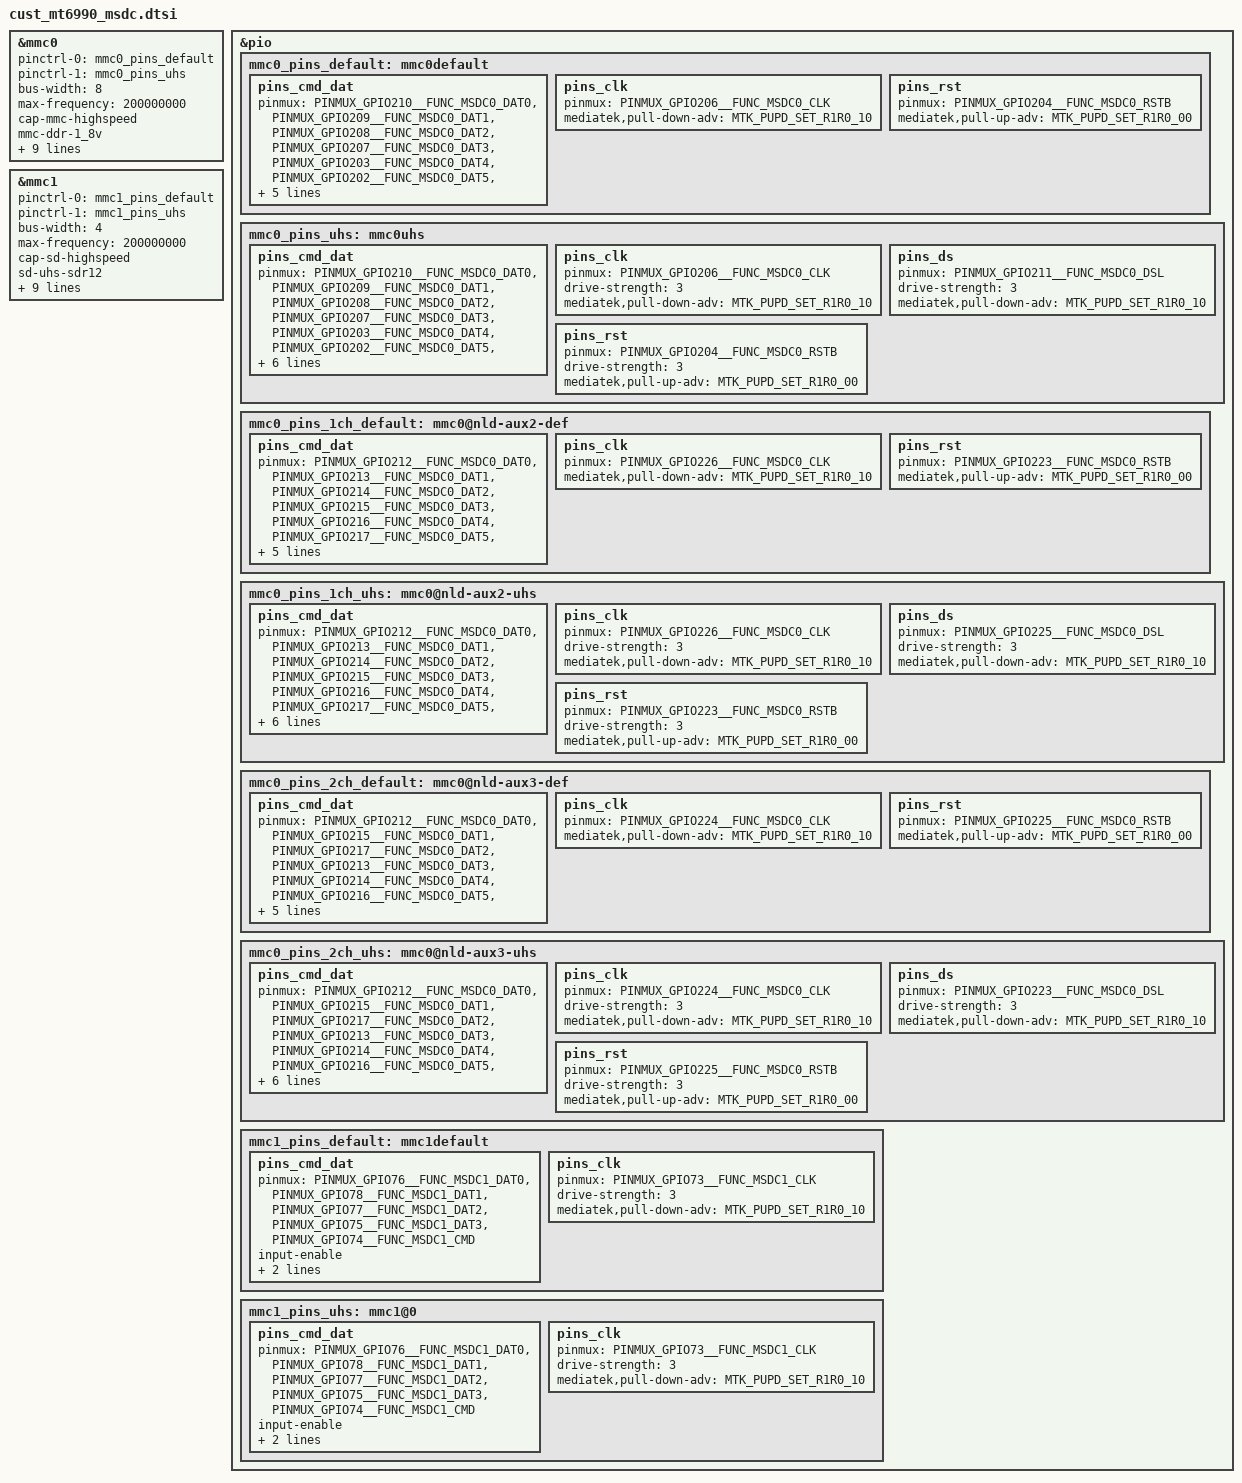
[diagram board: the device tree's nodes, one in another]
// SPDX-License-Identifier: GPL-2.0
/*
 * Copyright (c) 2019 MediaTek Inc.
 */
/********************************************
 * MT6890 MSDC DTSI File
 ********************************************/
#include <dt-bindings/gpio/gpio.h>

&mmc0 {
	pinctrl-names = "default", "state_uhs";
	pinctrl-0 = <&mmc0_pins_default>;
	pinctrl-1 = <&mmc0_pins_uhs>;
	bus-width = <8>;
	max-frequency = <200000000>;
	cap-mmc-highspeed;
	mmc-ddr-1_8v;
	mmc-hs200-1_8v;
	mmc-hs400-1_8v;
	cap-mmc-hw-reset;
	no-sdio;
	no-sd;
	hs400-ds-delay = <0x12814>;
	supports-cqe;
	power-gpio = <&pio 102 GPIO_ACTIVE_LOW>;
	non-removable;
};

&pio {
	mmc0_pins_default: mmc0default {
		pins_cmd_dat {
			pinmux = <PINMUX_GPIO210__FUNC_MSDC0_DAT0>,
					 <PINMUX_GPIO209__FUNC_MSDC0_DAT1>,
					 <PINMUX_GPIO208__FUNC_MSDC0_DAT2>,
					 <PINMUX_GPIO207__FUNC_MSDC0_DAT3>,
					 <PINMUX_GPIO203__FUNC_MSDC0_DAT4>,
					 <PINMUX_GPIO202__FUNC_MSDC0_DAT5>,
					 <PINMUX_GPIO201__FUNC_MSDC0_DAT6>,
					 <PINMUX_GPIO200__FUNC_MSDC0_DAT7>,
					 <PINMUX_GPIO205__FUNC_MSDC0_CMD>;
			input-enable;
			mediatek,pull-up-adv = <MTK_PUPD_SET_R1R0_01>;
		};
		pins_clk {
			pinmux = <PINMUX_GPIO206__FUNC_MSDC0_CLK>;
			mediatek,pull-down-adv = <MTK_PUPD_SET_R1R0_10>;
		};

		pins_rst {
			pinmux = <PINMUX_GPIO204__FUNC_MSDC0_RSTB>;
			mediatek,pull-up-adv = <MTK_PUPD_SET_R1R0_00>;
		};
	};
	mmc0_pins_uhs: mmc0uhs{
		pins_cmd_dat {
			pinmux = <PINMUX_GPIO210__FUNC_MSDC0_DAT0>,
					 <PINMUX_GPIO209__FUNC_MSDC0_DAT1>,
					 <PINMUX_GPIO208__FUNC_MSDC0_DAT2>,
					 <PINMUX_GPIO207__FUNC_MSDC0_DAT3>,
					 <PINMUX_GPIO203__FUNC_MSDC0_DAT4>,
					 <PINMUX_GPIO202__FUNC_MSDC0_DAT5>,
					 <PINMUX_GPIO201__FUNC_MSDC0_DAT6>,
					 <PINMUX_GPIO200__FUNC_MSDC0_DAT7>,
					 <PINMUX_GPIO205__FUNC_MSDC0_CMD>;
			input-enable;
			drive-strength = <3>;
			mediatek,pull-up-adv = <MTK_PUPD_SET_R1R0_01>;
		};
		pins_clk {
			pinmux = <PINMUX_GPIO206__FUNC_MSDC0_CLK>;
			drive-strength = <3>;
			mediatek,pull-down-adv = <MTK_PUPD_SET_R1R0_10>;
		};
		pins_ds {
			pinmux = <PINMUX_GPIO211__FUNC_MSDC0_DSL>;
			drive-strength = <3>;
			mediatek,pull-down-adv = <MTK_PUPD_SET_R1R0_10>;
		};
		pins_rst {
			pinmux = <PINMUX_GPIO204__FUNC_MSDC0_RSTB>;
			drive-strength = <3>;
			mediatek,pull-up-adv = <MTK_PUPD_SET_R1R0_00>;
		};
	};
	mmc0_pins_1ch_default: mmc0@nld-aux2-def{
		pins_cmd_dat {
			pinmux = <PINMUX_GPIO212__FUNC_MSDC0_DAT0>,
					 <PINMUX_GPIO213__FUNC_MSDC0_DAT1>,
					 <PINMUX_GPIO214__FUNC_MSDC0_DAT2>,
					 <PINMUX_GPIO215__FUNC_MSDC0_DAT3>,
					 <PINMUX_GPIO216__FUNC_MSDC0_DAT4>,
					 <PINMUX_GPIO217__FUNC_MSDC0_DAT5>,
					 <PINMUX_GPIO218__FUNC_MSDC0_DAT6>,
					 <PINMUX_GPIO219__FUNC_MSDC0_DAT7>,
					 <PINMUX_GPIO224__FUNC_MSDC0_CMD>;
			input-enable;
			mediatek,pull-up-adv = <MTK_PUPD_SET_R1R0_01>;
		};
		pins_clk {
			pinmux = <PINMUX_GPIO226__FUNC_MSDC0_CLK>;
			mediatek,pull-down-adv = <MTK_PUPD_SET_R1R0_10>;
		};

		pins_rst {
			pinmux = <PINMUX_GPIO223__FUNC_MSDC0_RSTB>;
			mediatek,pull-up-adv = <MTK_PUPD_SET_R1R0_00>;
		};
	};

	mmc0_pins_1ch_uhs: mmc0@nld-aux2-uhs{
		pins_cmd_dat {
			pinmux = <PINMUX_GPIO212__FUNC_MSDC0_DAT0>,
					 <PINMUX_GPIO213__FUNC_MSDC0_DAT1>,
					 <PINMUX_GPIO214__FUNC_MSDC0_DAT2>,
					 <PINMUX_GPIO215__FUNC_MSDC0_DAT3>,
					 <PINMUX_GPIO216__FUNC_MSDC0_DAT4>,
					 <PINMUX_GPIO217__FUNC_MSDC0_DAT5>,
					 <PINMUX_GPIO218__FUNC_MSDC0_DAT6>,
					 <PINMUX_GPIO219__FUNC_MSDC0_DAT7>,
					 <PINMUX_GPIO224__FUNC_MSDC0_CMD>;
			input-enable;
			drive-strength = <3>;
			mediatek,pull-up-adv = <MTK_PUPD_SET_R1R0_01>;
		};
		pins_clk {
			pinmux = <PINMUX_GPIO226__FUNC_MSDC0_CLK>;
			drive-strength = <3>;
			mediatek,pull-down-adv = <MTK_PUPD_SET_R1R0_10>;
		};
		pins_ds {
			pinmux = <PINMUX_GPIO225__FUNC_MSDC0_DSL>;
			drive-strength = <3>;
			mediatek,pull-down-adv = <MTK_PUPD_SET_R1R0_10>;
		};
		pins_rst {
			pinmux = <PINMUX_GPIO223__FUNC_MSDC0_RSTB>;
			drive-strength = <3>;
			mediatek,pull-up-adv = <MTK_PUPD_SET_R1R0_00>;
		};
	};

	mmc0_pins_2ch_default: mmc0@nld-aux3-def{
		pins_cmd_dat {
			pinmux = <PINMUX_GPIO212__FUNC_MSDC0_DAT0>,
					 <PINMUX_GPIO215__FUNC_MSDC0_DAT1>,
					 <PINMUX_GPIO217__FUNC_MSDC0_DAT2>,
					 <PINMUX_GPIO213__FUNC_MSDC0_DAT3>,
					 <PINMUX_GPIO214__FUNC_MSDC0_DAT4>,
					 <PINMUX_GPIO216__FUNC_MSDC0_DAT5>,
					 <PINMUX_GPIO218__FUNC_MSDC0_DAT6>,
					 <PINMUX_GPIO219__FUNC_MSDC0_DAT7>,
					 <PINMUX_GPIO226__FUNC_MSDC0_CMD>;
			input-enable;
			mediatek,pull-up-adv = <MTK_PUPD_SET_R1R0_01>;
		};
		pins_clk {
			pinmux = <PINMUX_GPIO224__FUNC_MSDC0_CLK>;
			mediatek,pull-down-adv = <MTK_PUPD_SET_R1R0_10>;
		};

		pins_rst {
			pinmux = <PINMUX_GPIO225__FUNC_MSDC0_RSTB>;
			mediatek,pull-up-adv = <MTK_PUPD_SET_R1R0_00>;
		};
	};
	mmc0_pins_2ch_uhs: mmc0@nld-aux3-uhs{
		pins_cmd_dat {
			pinmux = <PINMUX_GPIO212__FUNC_MSDC0_DAT0>,
					 <PINMUX_GPIO215__FUNC_MSDC0_DAT1>,
					 <PINMUX_GPIO217__FUNC_MSDC0_DAT2>,
					 <PINMUX_GPIO213__FUNC_MSDC0_DAT3>,
					 <PINMUX_GPIO214__FUNC_MSDC0_DAT4>,
					 <PINMUX_GPIO216__FUNC_MSDC0_DAT5>,
					 <PINMUX_GPIO218__FUNC_MSDC0_DAT6>,
					 <PINMUX_GPIO219__FUNC_MSDC0_DAT7>,
					 <PINMUX_GPIO226__FUNC_MSDC0_CMD>;
			input-enable;
			drive-strength = <3>;
			mediatek,pull-up-adv = <MTK_PUPD_SET_R1R0_01>;
		};
		pins_clk {
			pinmux = <PINMUX_GPIO224__FUNC_MSDC0_CLK>;
			drive-strength = <3>;
			mediatek,pull-down-adv = <MTK_PUPD_SET_R1R0_10>;
		};
		pins_ds {
			pinmux = <PINMUX_GPIO223__FUNC_MSDC0_DSL>;
			drive-strength = <3>;
			mediatek,pull-down-adv = <MTK_PUPD_SET_R1R0_10>;
		};
		pins_rst {
			pinmux = <PINMUX_GPIO225__FUNC_MSDC0_RSTB>;
			drive-strength = <3>;
			mediatek,pull-up-adv = <MTK_PUPD_SET_R1R0_00>;
		};
	};
};

&mmc1 {
	pinctrl-names = "default", "state_uhs";
	pinctrl-0 = <&mmc1_pins_default>;
	pinctrl-1 = <&mmc1_pins_uhs>;
//	pinctrl-2 = <&mmc1_a_pins_default>;
//	pinctrl-3 = <&mmc1_a_pins_uhs>;
	bus-width = <4>;
	max-frequency = <200000000>;
	cap-sd-highspeed;
	sd-uhs-sdr12;
	sd-uhs-sdr25;
	sd-uhs-sdr50;
	sd-uhs-sdr104;
	sd-uhs-ddr50;
	cd-gpios = <&pio 99 GPIO_ACTIVE_LOW>;
	power-gpio = <&pio 153 GPIO_ACTIVE_HIGH>;
	vqmmc-supply = <&mt6361_ldo28_vmc_reg>;
	no-mmc;
	no-sdio;
};

&pio {
#if 1
	mmc1_pins_default: mmc1default {
		pins_cmd_dat {
			pinmux = <PINMUX_GPIO76__FUNC_MSDC1_DAT0>,
					 <PINMUX_GPIO78__FUNC_MSDC1_DAT1>,
					 <PINMUX_GPIO77__FUNC_MSDC1_DAT2>,
					 <PINMUX_GPIO75__FUNC_MSDC1_DAT3>,
					 <PINMUX_GPIO74__FUNC_MSDC1_CMD>;
			input-enable;
			drive-strength = <3>;
			mediatek,pull-up-adv = <MTK_PUPD_SET_R1R0_01>;
		};

		pins_clk {
			pinmux = <PINMUX_GPIO73__FUNC_MSDC1_CLK>;
			drive-strength = <3>;
			mediatek,pull-down-adv = <MTK_PUPD_SET_R1R0_10>;
		};

//		pins_insert {
//			pinmux = <PINMUX_GPIO99__FUNC_GPIO99>;
//			bias-pull-up;
//		};
	};

	mmc1_pins_uhs: mmc1@0{
		pins_cmd_dat {
			pinmux = <PINMUX_GPIO76__FUNC_MSDC1_DAT0>,
					 <PINMUX_GPIO78__FUNC_MSDC1_DAT1>,
					 <PINMUX_GPIO77__FUNC_MSDC1_DAT2>,
					 <PINMUX_GPIO75__FUNC_MSDC1_DAT3>,
					 <PINMUX_GPIO74__FUNC_MSDC1_CMD>;
			input-enable;
			drive-strength = <3>;
			mediatek,pull-up-adv = <MTK_PUPD_SET_R1R0_01>;
		};

		pins_clk {
			pinmux = <PINMUX_GPIO73__FUNC_MSDC1_CLK>;
			drive-strength = <3>;
			mediatek,pull-down-adv = <MTK_PUPD_SET_R1R0_10>;
		};
	};
#endif
#if 0
	mmc1_pins_default: mmc1default {
		pins_cmd_dat {
			pinmux = <PINMUX_GPIO43__FUNC_MSDC1_DAT0_A>,
					 <PINMUX_GPIO44__FUNC_MSDC1_DAT1_A>,
					 <PINMUX_GPIO40__FUNC_MSDC1_DAT2_A>,
					 <PINMUX_GPIO39__FUNC_MSDC1_DAT3_A>,
					 <PINMUX_GPIO41__FUNC_MSDC1_CMD>;
			input-enable;
			drive-strength = <3>;
			mediatek,pull-up-adv = <MTK_PUPD_SET_R1R0_01>;
		};

		pins_clk {
			pinmux = <PINMUX_GPIO42__FUNC_MSDC1_CLK_A>;
			drive-strength = <3>;
			mediatek,pull-down-adv = <MTK_PUPD_SET_R1R0_10>;
		};

//		pins_insert {
//			pinmux = <PINMUX_GPIO14__FUNC_GPIO14>;
//			bias-pull-up;
//		};
	};

	mmc1_pins_uhs: mmc1@0{
		pins_cmd_dat {
			pinmux = <PINMUX_GPIO43__FUNC_MSDC1_DAT0_A>,
					 <PINMUX_GPIO44__FUNC_MSDC1_DAT1_A>,
					 <PINMUX_GPIO40__FUNC_MSDC1_DAT2_A>,
					 <PINMUX_GPIO39__FUNC_MSDC1_DAT3_A>,
					 <PINMUX_GPIO41__FUNC_MSDC1_CMD>;
			input-enable;
			drive-strength = <3>;
			mediatek,pull-up-adv = <MTK_PUPD_SET_R1R0_01>;
		};

		pins_clk {
			pinmux = <PINMUX_GPIO42__FUNC_MSDC1_CLK_A>;
			drive-strength = <3>;
			mediatek,pull-down-adv = <MTK_PUPD_SET_R1R0_10>;
		};
	};
#endif
};
